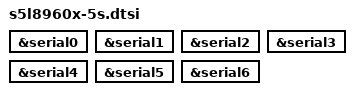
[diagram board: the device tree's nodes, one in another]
// SPDX-License-Identifier: GPL-2.0+ OR MIT
/*
 * Apple iPhone 5S common device tree
 * Based on A7 (APL0698), up to 1.3GHz
 *
 * Copyright (c) 2022, Konrad Dybcio <konrad.dybcio@somainline.org>
 */

#include "s5l8960x.dtsi"

/ {
};

&serial0 {
	status = "okay";
};

&serial1 {
	status = "okay";

	/* Bluetooth chip, probably brcm,bcm4334-bt (needs Oscar pinctrl) */
};

&serial2 {
	status = "okay";

	/* Apple Oscar sensor hub */
};

&serial3 {
	status = "okay";

	/* WLAN debug device */
};

&serial4 {
	status = "okay";

	/* Apple 'debug' device (?) */
};

&serial5 {
	status = "okay";

	/* bq27540 fuel gauge */
};

&serial6 {
	status = "okay";

	/* Apple IAP (something related to Lightning?) */
};
